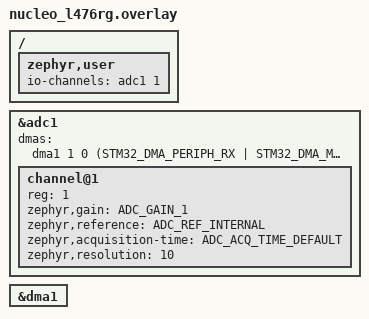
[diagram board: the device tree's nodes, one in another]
/*
 * SPDX-License-Identifier: Apache-2.0
 *
 * Copyright (c) Benjamin Björnsson <benjamin.bjornsson@gmail.com>
 */

/ {
	zephyr,user {
		/* adjust channel number according to pinmux in board.dts */
		io-channels = <&adc1 1>;
	};
};

&adc1 {
	dmas = <&dma1 1 0 (STM32_DMA_PERIPH_RX | STM32_DMA_MEM_16BITS | STM32_DMA_PERIPH_16BITS)>;
	dma-names = "dma";

	#address-cells = <1>;
	#size-cells = <0>;

	channel@1 {
		reg = <1>;
		zephyr,gain = "ADC_GAIN_1";
		zephyr,reference = "ADC_REF_INTERNAL";
		zephyr,acquisition-time = <ADC_ACQ_TIME_DEFAULT>;
		zephyr,resolution = <10>;
	};
};

&dma1 {
	status = "okay";
};
